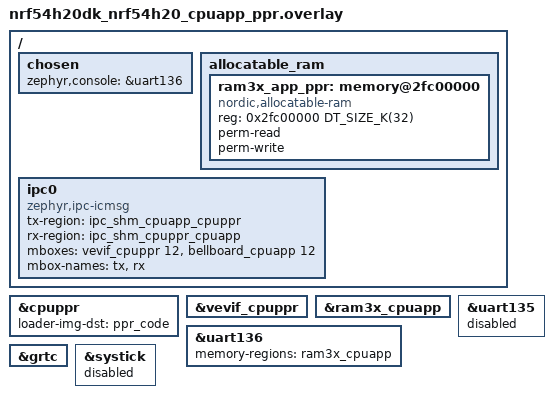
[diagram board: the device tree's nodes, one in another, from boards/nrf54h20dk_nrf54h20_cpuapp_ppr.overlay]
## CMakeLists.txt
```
#
# Copyright (c) 2022 Nordic Semiconductor ASA
#
# SPDX-License-Identifier: Apache-2.0
#

cmake_minimum_required(VERSION 3.20.0)

if (CONF_FILE AND NOT DEFINED DTC_OVERLAY_FILE)
  if(${CONF_FILE} MATCHES "prj_(.*).conf")
    set(DTC_OVERLAY_FILE "${CMAKE_MATCH_1}.overlay")
  endif()
endif()

# Use config file with the same name in remote.
if (CONF_FILE AND NOT DEFINED remote_CONF_FILE)
  set(remote_CONF_FILE ${CONF_FILE})
endif()

# Use DTC overlay file with the same name in remote
if (DTC_OVERLAY_FILE AND NOT DEFINED remote_DTC_OVERLAY_FILE)
  set(remote_DTC_OVERLAY_FILE ${DTC_OVERLAY_FILE})
endif()

# Use config overlay with the same name in remote.
if(OVERLAY_CONFIG AND NOT DEFINED remote_OVERLAY_CONFIG)
  set(remote_OVERLAY_CONFIG ${OVERLAY_CONFIG})
endif()

set(ZEPHYR_EXTRA_MODULES ${CMAKE_CURRENT_LIST_DIR})

find_package(Zephyr REQUIRED HINTS $ENV{ZEPHYR_BASE})
project(ipc_service_host)

target_sources(app PRIVATE src/main.c)
```

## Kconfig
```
#
# Copyright (c) 2022 Nordic Semiconductor ASA
#
# SPDX-License-Identifier: LicenseRef-Nordic-5-Clause
#

source "Kconfig.zephyr"
rsource "Kconfig.app"

config APP_INCLUDE_REMOTE_IMAGE
	bool "Include remote image as sub image"
	depends on SOC_NRF5340_CPUAPP || SOC_PLATFORM_HALTIUM
	default y if (BOARD_NRF5340DK_NRF5340_CPUAPP || BOARD_NRF5340DK_NRF5340_CPUAPPNS)
	default y if (BOARD_NRF54H20DK_NRF54H20_CPUAPP || BOARD_NRF7140DK_NRF7140_CPUAPP || BOARD_NRF9230DK_NRF9230_CPUAPP)
	select PARTITION_MANAGER_ENABLED if SOC_NRF5340_CPUAPP
	select BOARD_ENABLE_CPUNET if (BOARD_NRF5340DK_NRF5340_CPUAPP || BOARD_NRF5340DK_NRF5340_CPUAPPNS)

config APP_REMOTE_BOARD
	string "The name of the board to be used by remote image"
	depends on APP_INCLUDE_REMOTE_IMAGE
	default DOMAIN_CPUNET_BOARD if (BOARD_NRF5340DK_NRF5340_CPUAPP || BOARD_NRF5340DK_NRF5340_CPUAPPNS)
	default "nrf54h20dk_nrf54h20_cpuppr@soc1" if (BOARD_NRF54H20DK_NRF54H20_CPUAPP && HW_REVISION_SOC1)
	default "nrf7140dk_nrf7140_cpuppr" if BOARD_NRF7140DK_NRF7140_CPUAPP
	default "nrf9230dk_nrf9230_cpuppr" if BOARD_NRF9230DK_NRF9230_CPUAPP
```

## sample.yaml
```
sample:
    name: IPC Service integration test
    description: IPC Service integration and efficiency test
tests:
  sample.ipc.ipc_service.rpmsg_default:
    build_only: true
    platform_allow: nrf5340dk_nrf5340_cpuapp
    integration_platforms:
      - nrf5340dk_nrf5340_cpuapp
    tags: ipc
  sample.ipc.ipc_service.rpmsg_cpuapp_sending:
    build_only: true
    platform_allow: nrf5340dk_nrf5340_cpuapp
    integration_platforms:
      - nrf5340dk_nrf5340_cpuapp
    tags: ipc
    extra_args:
      OVERLAY_CONFIG=overlay-cpuapp-sending.conf
  sample.ipc.ipc_service.rpmsg_cpunet_sending:
    build_only: true
    platform_allow: nrf5340dk_nrf5340_cpuapp
    integration_platforms:
      - nrf5340dk_nrf5340_cpuapp
    tags: ipc
    extra_args:
      OVERLAY_CONFIG=overlay-cpunet-sending.conf
  sample.ipc.ipc_service.icmsg_default:
    build_only: true
    platform_allow: nrf5340dk_nrf5340_cpuapp
    integration_platforms:
      - nrf5340dk_nrf5340_cpuapp
    tags: ipc
    extra_args:
      CONF_FILE=prj_icmsg.conf
  sample.ipc.ipc_service.icmsg_cpuapp_sending:
    build_only: true
    platform_allow: nrf5340dk_nrf5340_cpuapp
    integration_platforms:
      - nrf5340dk_nrf5340_cpuapp
    tags: ipc
    extra_args:
      CONF_FILE=prj_icmsg.conf
      OVERLAY_CONFIG=overlay-cpuapp-sending.conf
  sample.ipc.ipc_service.icmsg_cpunet_sending:
    build_only: true
    platform_allow: nrf5340dk_nrf5340_cpuapp
    integration_platforms:
      - nrf5340dk_nrf5340_cpuapp
    tags: ipc
    extra_args:
      CONF_FILE=prj_icmsg.conf
      OVERLAY_CONFIG=overlay-cpunet-sending.conf

# Haltium Platform
  sample.ipc.ipc_service.nrf54_app_rad_icmsg:
    build_only: true
    platform_allow: nrf54h20dk_nrf54h20_cpuapp@soc1
    integration_platforms:
      - nrf54h20dk_nrf54h20_cpuapp@soc1
    tags: ipc
    extra_args:
      CONF_FILE=prj_icmsg.conf
      OVERLAY_CONFIG=boards/nrf54h20dk_nrf54h20_cpuapp_rad.conf
      DTC_OVERLAY_FILE=boards/nrf54h20dk_nrf54h20_cpuapp_rad_icmsg.overlay

  sample.ipc.ipc_service.nrf54_app_rad_rpmsg:
    build_only: true
    platform_allow: nrf54h20dk_nrf54h20_cpuapp@soc1
    integration_platforms:
      - nrf54h20dk_nrf54h20_cpuapp@soc1
    tags: ipc
    extra_args:
      OVERLAY_CONFIG=boards/nrf54h20dk_nrf54h20_cpuapp_rad.conf
      DTC_OVERLAY_FILE=boards/nrf54h20dk_nrf54h20_cpuapp_rad.overlay
      CONFIG_APP_IPC_SERVICE_SEND_INTERVAL=100
      remote_CONFIG_APP_IPC_SERVICE_SEND_INTERVAL=100

  sample.ipc.ipc_service.nrf54_app_rad_gpio_latency_icmsg:
    build_only: true
    platform_allow: nrf54h20dk_nrf54h20_cpuapp@soc1
    integration_platforms:
      - nrf54h20dk_nrf54h20_cpuapp@soc1
    tags: ipc
    extra_args:
      CONF_FILE=prj_icmsg.conf
      OVERLAY_CONFIG=boards/nrf54h20dk_nrf54h20_cpuapp_rad.conf
      DTC_OVERLAY_FILE=boards/nrf54h20dk_nrf54h20_cpuapp_rad_icmsg.overlay;boards/nrf54h20dk_nrf54h20_cpuapp_gpio_latency.overlay
      remote_DTC_OVERLAY_FILE=boards/nrf54h20dk_nrf54h20_cpuapp_rad_icmsg.overlay;boards/nrf54h20dk_nrf54h20_cpurad_gpio_latency.overlay
      CONFIG_APP_IPC_SERVICE_SEND_INTERVAL=10000
      remote_CONFIG_APP_IPC_SERVICE_SEND_INTERVAL=10000
      CONFIG_GPIO=y
      remote_CONFIG_GPIO=y
  sample.ipc.ipc_service.nrf54_app_rad_gpio_latency_rpmsg:
    build_only: true
    platform_allow: nrf54h20dk_nrf54h20_cpuapp@soc1
    integration_platforms:
      - nrf54h20dk_nrf54h20_cpuapp@soc1
    tags: ipc
    extra_args:
      OVERLAY_CONFIG=boards/nrf54h20dk_nrf54h20_cpuapp_rad.conf
      DTC_OVERLAY_FILE=boards/nrf54h20dk_nrf54h20_cpuapp_rad.overlay;boards/nrf54h20dk_nrf54h20_cpuapp_gpio_latency.overlay
      remote_DTC_OVERLAY_FILE=boards/nrf54h20dk_nrf54h20_cpuapp_rad.overlay;boards/nrf54h20dk_nrf54h20_cpurad_gpio_latency.overlay
      CONFIG_APP_IPC_SERVICE_SEND_INTERVAL=10000
      remote_CONFIG_APP_IPC_SERVICE_SEND_INTERVAL=10000
      CONFIG_GPIO=y
      remote_CONFIG_GPIO=y

  sample.ipc.ipc_service.nrf54_app_ppr_icmsg:
    build_only: true
    platform_allow: nrf54h20dk_nrf54h20_cpuapp@soc1
    integration_platforms:
      - nrf54h20dk_nrf54h20_cpuapp@soc1
    tags: ipc
    extra_args:
      CONF_FILE=prj_icmsg.conf
      OVERLAY_CONFIG=boards/nrf54h20dk_nrf54h20_cpuapp_ppr.conf
      DTC_OVERLAY_FILE=boards/nrf54h20dk_nrf54h20_cpuapp_ppr.overlay

  sample.ipc.ipc_service.nrf54_app_sys_icmsg:
    build_only: true
    platform_allow: nrf54h20dk_nrf54h20_cpuapp@soc1
    integration_platforms:
      - nrf54h20dk_nrf54h20_cpuapp@soc1
    tags: ipc
    extra_args:
      CONF_FILE=prj_icmsg.conf
      OVERLAY_CONFIG=boards/nrf54h20dk_nrf54h20_cpuapp_sys.conf
      DTC_OVERLAY_FILE=boards/nrf54h20dk_nrf54h20_cpuapp_sys_icmsg.overlay

  sample.ipc.ipc_service.nrf54_rad_sys_icmsg:
    build_only: true
    platform_allow: nrf54h20dk_nrf54h20_cpurad@soc1
    integration_platforms:
      - nrf54h20dk_nrf54h20_cpurad@soc1
    tags: ipc
    extra_args:
      CONF_FILE=prj_icmsg.conf
      OVERLAY_CONFIG=boards/nrf54h20dk_nrf54h20_cpurad_sys.conf
      DTC_OVERLAY_FILE=boards/nrf54h20dk_nrf54h20_cpurad_sys_icmsg.overlay

  sample.ipc.ipc_service.nrf71_app_ppr_icmsg:
    build_only: true
    platform_allow: nrf7140dk_nrf7140_cpuapp
    integration_platforms:
      - nrf7140dk_nrf7140_cpuapp
    tags: ipc
    extra_args:
      CONF_FILE=prj_icmsg.conf
      OVERLAY_CONFIG=boards/nrf7140dk_nrf7140_cpuapp_ppr.conf
      DTC_OVERLAY_FILE=boards/nrf7140dk_nrf7140_cpuapp_ppr.overlay

  sample.ipc.ipc_service.nrf92_app_ppr_icmsg:
    build_only: true
    platform_allow: nrf9230dk_nrf9230_cpuapp
    integration_platforms:
      - nrf9230dk_nrf9230_cpuapp
    tags: ipc
    extra_args:
      CONF_FILE=prj_icmsg.conf
      OVERLAY_CONFIG=boards/nrf9230dk_nrf9230_cpuapp_ppr.conf
      DTC_OVERLAY_FILE=boards/nrf9230dk_nrf9230_cpuapp_ppr.overlay
      remote_CONFIG_EMULATOR_FPGA=y
      CONFIG_EMULATOR_FPGA=y

  sample.ipc.ipc_service.nrf92_app_rad_icmsg:
    build_only: true
    platform_allow: nrf9230dk_nrf9230_cpuapp
    integration_platforms:
      - nrf9230dk_nrf9230_cpuapp
    tags: ipc
    extra_args:
      CONF_FILE=prj_icmsg.conf
      OVERLAY_CONFIG=boards/nrf9230dk_nrf9230_cpuapp_rad.conf
      DTC_OVERLAY_FILE=boards/nrf9230dk_nrf9230_cpuapp_rad_icmsg.overlay
      remote_CONFIG_EMULATOR_FPGA=y
      CONFIG_EMULATOR_FPGA=y

  sample.ipc.ipc_service.nrf92_app_sys_icmsg:
    build_only: true
    platform_allow: nrf9230dk_nrf9230_cpuapp
    integration_platforms:
      - nrf9230dk_nrf9230_cpuapp
    tags: ipc
    extra_args:
      CONF_FILE=prj_icmsg.conf
      OVERLAY_CONFIG=boards/nrf9230dk_nrf9230_cpuapp_sys.conf
      DTC_OVERLAY_FILE=boards/nrf9230dk_nrf9230_cpuapp_sys_icmsg.overlay
      remote_CONFIG_EMULATOR_FPGA=y
      CONFIG_EMULATOR_FPGA=y

  sample.ipc.ipc_service.nrf92_rad_sys_icmsg:
    build_only: true
    platform_allow: nrf9230dk_nrf9230_cpurad
    integration_platforms:
      - nrf9230dk_nrf9230_cpurad
    tags: ipc
    extra_args:
      CONF_FILE=prj_icmsg.conf
      OVERLAY_CONFIG=boards/nrf9230dk_nrf9230_cpurad_sys.conf
      DTC_OVERLAY_FILE=boards/nrf9230dk_nrf9230_cpurad_sys_icmsg.overlay
      remote_CONFIG_EMULATOR_FPGA=y
      CONFIG_EMULATOR_FPGA=y

  sample.ipc.ipc_service.nrf92_app_mod_icmsg:
    build_only: true
    platform_allow: nrf9230dk_nrf9230_cpuapp
    integration_platforms:
      - nrf9230dk_nrf9230_cpuapp
    tags: ipc
    extra_args:
      CONF_FILE=prj_icmsg.conf
      OVERLAY_CONFIG=boards/nrf9230dk_nrf9230_cpuapp_mod.conf
      DTC_OVERLAY_FILE=boards/nrf9230dk_nrf9230_cpuapp_mod_icmsg.overlay
      remote_CONFIG_EMULATOR_FPGA=y
      CONFIG_EMULATOR_FPGA=y

  sample.ipc.ipc_service.nrf92_app_rad_rpmsg:
    build_only: true
    platform_allow: nrf9230dk_nrf9230_cpuapp
    integration_platforms:
      - nrf9230dk_nrf9230_cpuapp
    tags: ipc
    extra_args:
      OVERLAY_CONFIG=boards/nrf9230dk_nrf9230_cpuapp_rad.conf
      DTC_OVERLAY_FILE=boards/nrf9230dk_nrf9230_cpuapp_rad.overlay
      CONFIG_APP_IPC_SERVICE_SEND_INTERVAL=100
      remote_CONFIG_APP_IPC_SERVICE_SEND_INTERVAL=100
      remote_CONFIG_EMULATOR_FPGA=y
      CONFIG_EMULATOR_FPGA=y

  sample.ipc.ipc_service.nrf92_app_mod_rpmsg:
    build_only: true
    platform_allow: nrf9230dk_nrf9230_cpuapp
    integration_platforms:
      - nrf9230dk_nrf9230_cpuapp
    tags: ipc
    extra_args:
      OVERLAY_CONFIG=boards/nrf9230dk_nrf9230_cpuapp_mod.conf
      DTC_OVERLAY_FILE=boards/nrf9230dk_nrf9230_cpuapp_mod.overlay
      CONFIG_APP_IPC_SERVICE_SEND_INTERVAL=100
      remote_CONFIG_APP_IPC_SERVICE_SEND_INTERVAL=100
      remote_CONFIG_EMULATOR_FPGA=y
      CONFIG_EMULATOR_FPGA=y
```

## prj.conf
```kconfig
CONFIG_IPC_SERVICE=y

CONFIG_PRINTK=y
CONFIG_LOG=y
CONFIG_IPC_SERVICE_LOG_LEVEL_INF=y
CONFIG_IPC_SERVICE_BACKEND_RPMSG=y
CONFIG_IPC_SERVICE_STATIC_VRINGS_MEM_ALIGNMENT=32
CONFIG_MBOX=y

# required to allocate virtqueues
CONFIG_HEAP_MEM_POOL_SIZE=4096

CONFIG_OPENAMP=y
CONFIG_OPENAMP_SLAVE=n
CONFIG_OPENAMP_WITH_DCACHE=y

CONFIG_LOG_PROCESS_THREAD_PRIORITY=-15
CONFIG_LOG_PROCESS_THREAD_CUSTOM_PRIORITY=y
```

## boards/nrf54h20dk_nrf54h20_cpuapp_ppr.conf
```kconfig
#
# Copyright (c) 2022 Nordic Semiconductor ASA
#
# SPDX-License-Identifier: LicenseRef-Nordic-5-Clause
#

CONFIG_MBOX_NRFX_IDS=y

CONFIG_APP_IPC_SERVICE_SEND_INTERVAL=900

CONFIG_UART_CONSOLE=y
CONFIG_CONSOLE=y
CONFIG_SERIAL=y
```

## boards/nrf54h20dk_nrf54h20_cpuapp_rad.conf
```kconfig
#
# Copyright (c) 2022 Nordic Semiconductor ASA
#
# SPDX-License-Identifier: LicenseRef-Nordic-5-Clause
#

CONFIG_MBOX_NRFX_IDS=y
CONFIG_APP_REMOTE_BOARD="nrf54h20dk_nrf54h20_cpurad@soc1"

CONFIG_APP_IPC_SERVICE_SEND_INTERVAL=900

CONFIG_UART_CONSOLE=y
CONFIG_CONSOLE=y
CONFIG_SERIAL=y
```

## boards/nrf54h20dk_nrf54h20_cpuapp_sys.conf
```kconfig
#
# Copyright (c) 2022 Nordic Semiconductor ASA
#
# SPDX-License-Identifier: LicenseRef-Nordic-5-Clause
#

CONFIG_MBOX_NRFX_IDS=y
CONFIG_APP_REMOTE_BOARD="nrf54h20dk_nrf54h20_cpusys@soc1"
CONFIG_INCLUDE_SYSCTRL=n

CONFIG_APP_IPC_SERVICE_SEND_INTERVAL=900

CONFIG_UART_CONSOLE=y
CONFIG_CONSOLE=y
CONFIG_SERIAL=y
```

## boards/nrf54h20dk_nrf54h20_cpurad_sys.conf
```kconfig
#
# Copyright (c) 2022 Nordic Semiconductor ASA
#
# SPDX-License-Identifier: LicenseRef-Nordic-5-Clause
#

CONFIG_MBOX_NRFX_IDS=y
CONFIG_APP_INCLUDE_REMOTE_IMAGE=y
CONFIG_APP_REMOTE_BOARD="nrf54h20dk_nrf54h20_cpusys@soc1"
CONFIG_INCLUDE_SYSCTRL=n

CONFIG_APP_IPC_SERVICE_SEND_INTERVAL=900

CONFIG_UART_CONSOLE=y
CONFIG_CONSOLE=y
CONFIG_SERIAL=y
```

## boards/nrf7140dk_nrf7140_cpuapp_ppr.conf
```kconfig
#
# Copyright (c) 2023 Nordic Semiconductor ASA
#
# SPDX-License-Identifier: LicenseRef-Nordic-5-Clause
#

CONFIG_MBOX_NRFX_IDS=y

CONFIG_APP_IPC_SERVICE_SEND_INTERVAL=900

CONFIG_UART_CONSOLE=y
CONFIG_CONSOLE=y
CONFIG_SERIAL=y
```

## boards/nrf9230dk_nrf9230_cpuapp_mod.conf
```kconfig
#
# Copyright (c) 2023 Nordic Semiconductor ASA
#
# SPDX-License-Identifier: LicenseRef-Nordic-5-Clause
#

CONFIG_MBOX_NRFX_IDS=y
CONFIG_APP_REMOTE_BOARD="nrf9230dk_nrf9230_cpumod"

CONFIG_APP_IPC_SERVICE_SEND_INTERVAL=900

CONFIG_UART_CONSOLE=y
CONFIG_CONSOLE=y
CONFIG_SERIAL=y
```

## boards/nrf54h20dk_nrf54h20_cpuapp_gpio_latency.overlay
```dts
/*
 * Copyright (c) 2023 Nordic Semiconductor ASA
 *
 * SPDX-License-Identifier: Apache-2.0
 *
 * This file is used to add the pins that would go high
 * when the ipc_service_send function is called and
 * while the receiving callback is processing the data.
 */

/ {
	ipc_send_pin: ipc-send-pin {
		compatible = "nordic,gpio-pins";
		gpios = <&gpio0 0 GPIO_ACTIVE_HIGH>;
		status = "okay";
	};

	ipc_recv_pin: ipc-recv-pin {
		compatible = "nordic,gpio-pins";
		gpios = <&gpio0 1 GPIO_ACTIVE_HIGH>;
		status = "okay";
	};
};

&gpio0 {
	status = "okay";
};
```

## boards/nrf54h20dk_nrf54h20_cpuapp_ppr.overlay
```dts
/*
 * Copyright (c) 2022 Nordic Semiconductor ASA
 *
 * SPDX-License-Identifier: LicenseRef-Nordic-5-Clause
 */



/ {
	chosen {
		zephyr,console = &uart136;
	};

	allocatable_ram {
		#address-cells = <1>;
		#size-cells = <1>;

		/* Configure RAM region.
		 * This is done to ensure correct UICR generation.
		 */
		ram3x_app_ppr: memory@2fc00000 {
			compatible = "nordic,allocatable-ram";
			reg = <0x2fc00000 DT_SIZE_K(32)>;
			perm-read;
			perm-write;
		};
	};

	ipc0: ipc0 {
		compatible = "zephyr,ipc-icmsg";
		tx-region = <&ipc_shm_cpuapp_cpuppr>;
		rx-region = <&ipc_shm_cpuppr_cpuapp>;
		mboxes = <&vevif_cpuppr 12>,
			 <&bellboard_cpuapp  12>;
		mbox-names = "tx", "rx";
		status = "okay";
	};
};

&cpuppr {
	loader-img-dst = <&ppr_code>;
	status = "okay";
};

&vevif_cpuppr {
       status = "okay";
};

&ram3x_cpuapp {
	status = "okay";
};

&uart136 {
	status = "okay";
	memory-regions = <&ram3x_cpuapp>;
};

&uart135 {
	status = "reserved";
};

&grtc {
	status = "okay";
};

&systick {
	status = "disabled";
};
```

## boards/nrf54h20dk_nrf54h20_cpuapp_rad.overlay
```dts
/*
 * Copyright (c) 2022 Nordic Semiconductor ASA
 *
 * SPDX-License-Identifier: Apache-2.0
 */

#include <common/nordic_nrf_next/nrfx_ram3x_dma.dtsi>

/{
	chosen {
		zephyr,console = &uart136;
		zephyr,sram = &cpuapp_ram0;
	};

	ipc0: ipc0 {
		compatible = "zephyr,ipc-openamp-static-vrings";
		memory-region = <&ipc_shm_area_cpuapp_cpurad>;
		mboxes = <&bellboard_cpurad 12>,
			 <&bellboard_cpuapp 18>;
		mbox-names = "tx", "rx";
		role = "host";
		status = "okay";
	};
};

/* ram3x_cpuapp buffer is used by App core UART driver. */
&ram3x_cpuapp {
	status = "okay";
};

&uart136 {
	status = "okay";
	memory-regions = <&ram3x_cpuapp>;
};
```

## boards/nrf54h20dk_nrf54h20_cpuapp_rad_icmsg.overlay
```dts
/*
 * Copyright (c) 2022 Nordic Semiconductor ASA
 *
 * SPDX-License-Identifier: Apache-2.0
 */


/{
	chosen {
		zephyr,console = &uart136;
	};

	allocatable_ram {
		#address-cells = <1>;
		#size-cells = <1>;

		ram3x_app_mem: memory@2fc00000 {
			compatible = "nordic,allocatable-ram";
			reg = <0x2fc00000 DT_SIZE_K(32)>;
			perm-read;
			perm-write;
		};
	};
};

&ipc_cpurad {
	compatible = "zephyr,ipc-icmsg";
	tx-region = <&ipc_shm_cpuapp_cpurad>;
	rx-region = <&ipc_shm_cpurad_cpuapp>;
	status = "okay";
	/delete-property/ memory-region;
	/delete-property/ role;
};

ipc0: &ipc_cpurad { };

/* ram3x_cpuapp buffer is used by App core UART driver. */
&ram3x_cpuapp {
	status = "okay";
};

&uart136 {
	status = "okay";
	memory-regions = <&ram3x_cpuapp>;
};
```

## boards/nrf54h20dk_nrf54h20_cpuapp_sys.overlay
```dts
/*
 * Copyright (c) 2022 Nordic Semiconductor ASA
 *
 * SPDX-License-Identifier: Apache-2.0
 */

#include <common/nordic_nrf_next/nrfx_ram3x_dma.dtsi>
#include "shared/nrf54_ipc_shm_ram2.dtsi"

/{
	chosen {
		zephyr,console = &uart136;
	};

	ipc0: ipc0 {
		compatible = "zephyr,ipc-openamp-static-vrings";
		memory-region = <&ipc_shm_ram>;
		mboxes = <&vevif_cpusys 12>,
			 <&bellboard_cpuapp 6>;
		mbox-names = "tx", "rx";
		role = "host";
		status = "okay";
	};
};

&vevif_cpusys {
	status = "okay";
};

/* ram3x_cpuapp buffer is used by App core UART driver. */
&ram3x_cpuapp {
	status = "okay";
};

&uart135 {
	status = "disabled";
};

&uart136 {
	status = "okay";
	memory-regions = <&ram3x_cpuapp>;
};
```

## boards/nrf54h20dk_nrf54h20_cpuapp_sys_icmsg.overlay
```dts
/*
 * Copyright (c) 2022 Nordic Semiconductor ASA
 *
 * SPDX-License-Identifier: Apache-2.0
 */

#include <common/nordic_nrf_next/nrfx_ram3x_dma.dtsi>
#include "shared/nrf54_ipc_shm_ram2.dtsi"

/ {
	chosen {
		zephyr,console = &uart136;
	};

	ipc0: ipc0 {
		compatible = "zephyr,ipc-icmsg";
		tx-region = <&ipc_shm_remote>;
		rx-region = <&ipc_shm_local>;
		mboxes = <&vevif_cpusys 12>,
			 <&bellboard_cpuapp 6>;
		mbox-names = "tx", "rx";
		status = "okay";
	};
};

&vevif_cpusys {
	status = "okay";
};

/* ram3x_cpuapp buffer is used by App core UART driver. */
&ram3x_cpuapp {
	status = "okay";
};

&uart135 {
	status = "disabled";
};

&uart136 {
	status = "okay";
	memory-regions = <&ram3x_cpuapp>;
};
```

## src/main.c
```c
/*
 * Copyright (c) 2022 Nordic Semiconductor ASA
 *
 * SPDX-License-Identifier: Apache-2.0
 */

#include <zephyr/kernel.h>
#include <zephyr/device.h>
#include <zephyr/drivers/gpio.h>
#include <string.h>

#include <zephyr/logging/log.h>

#include <zephyr/ipc/ipc_service.h>

#ifdef CONFIG_TEST_EXTRA_STACK_SIZE
#define STACKSIZE	(1024 + CONFIG_TEST_EXTRA_STACK_SIZE)
#else
#define STACKSIZE	(1024)
#endif

static const struct gpio_dt_spec pin_send =
	GPIO_DT_SPEC_GET_OR(DT_NODELABEL(ipc_send_pin), gpios, {0});
static const struct gpio_dt_spec pin_recv =
	GPIO_DT_SPEC_GET_OR(DT_NODELABEL(ipc_recv_pin), gpios, {0});

LOG_MODULE_REGISTER(host, LOG_LEVEL_INF);

struct payload {
	unsigned long cnt;
	unsigned long size;
	uint8_t data[];
};

static K_SEM_DEFINE(bound_sem, 0, 1);
K_THREAD_STACK_DEFINE(check_task_stack, STACKSIZE);
struct k_thread check_task_data;

static uint32_t payload_data[(CONFIG_APP_IPC_SERVICE_MESSAGE_LEN + 3)/4];
static struct payload *p_payload = (struct payload *) payload_data;

static void ep_bound(void *priv)
{
	k_sem_give(&bound_sem);
}

static void ep_recv(const void *data, size_t len, void *priv)
{
	uint8_t received_val = *((uint8_t *)data);
	static uint8_t expected_val;

	if (pin_recv.port) {
		gpio_pin_set_dt(&pin_recv, 1);
	}

	if ((received_val != expected_val) || (len != CONFIG_APP_IPC_SERVICE_MESSAGE_LEN)) {
		printk("Unexpected message received_val: %d , expected_val: %d\n",
			received_val,
			expected_val);
	}

	expected_val++;
	if (pin_recv.port) {
		gpio_pin_set_dt(&pin_recv, 0);
	}
}

static struct ipc_ept_cfg ep_cfg = {
	.name = "ep0",
	.cb = {
		.bound    = ep_bound,
		.received = ep_recv,
	},
};

static void check_task(void *arg1, void *arg2, void *arg3)
{
	ARG_UNUSED(arg1);
	ARG_UNUSED(arg2);
	ARG_UNUSED(arg3);

	unsigned long last_cnt = p_payload->cnt;
	unsigned long delta;

	while (1) {
		k_sleep(K_MSEC(1000));

		delta = p_payload->cnt - last_cnt;

		printk("Δpkt: %ld (%ld B/pkt) | throughput: %ld bit/s\n",
			delta, p_payload->size, delta * CONFIG_APP_IPC_SERVICE_MESSAGE_LEN * 8);

		last_cnt = p_payload->cnt;
	}
}

int main(void)
{
	const struct device *ipc0_instance;
	struct ipc_ept ep;
	int ret;
	printk("IPC-service %s demo started\n", CONFIG_BOARD);

	if (pin_send.port) {
		gpio_pin_configure_dt(&pin_send, GPIO_OUTPUT_INACTIVE);
	}
	if (pin_recv.port) {
		gpio_pin_configure_dt(&pin_recv, GPIO_OUTPUT_INACTIVE);
	}

	memset(p_payload->data, 0xA5, CONFIG_APP_IPC_SERVICE_MESSAGE_LEN - sizeof(struct payload));

	p_payload->size = CONFIG_APP_IPC_SERVICE_MESSAGE_LEN;
	p_payload->cnt = 0;

	ipc0_instance = DEVICE_DT_GET(DT_NODELABEL(ipc0));

	ret = ipc_service_open_instance(ipc0_instance);
	if ((ret < 0) && (ret != -EALREADY)) {
		LOG_INF("ipc_service_open_instance() failure: %d", ret);
		return ret;
	}

	ret = ipc_service_register_endpoint(ipc0_instance, &ep, &ep_cfg);
	if (ret < 0) {
		printf("ipc_service_register_endpoint() failure");
		return ret;
	}

	k_sem_take(&bound_sem, K_FOREVER);

	(void)k_thread_create(
		&check_task_data, check_task_stack,
		K_THREAD_STACK_SIZEOF(check_task_stack),
		check_task,
		NULL, NULL, NULL,
		-1, 0, K_NO_WAIT);

	while (true) {
		if (pin_send.port) {
			gpio_pin_set_dt(&pin_send, 1);
		}
		ret = ipc_service_send(&ep, p_payload, CONFIG_APP_IPC_SERVICE_MESSAGE_LEN);
		if (pin_send.port) {
			gpio_pin_set_dt(&pin_send, 0);
		}
		if (ret == -ENOMEM) {
			/* No space in the buffer. Retry. */
			LOG_DBG("send_message(%ld) failed with ret -ENOMEM\n", p_payload->cnt);
		} else if (ret < 0) {
			LOG_ERR("send_message(%ld) failed with ret %d\n", p_payload->cnt, ret);
			break;
		} else {
			p_payload->cnt++;
		}

		if (CONFIG_APP_IPC_SERVICE_SEND_INTERVAL < (USEC_PER_SEC / CONFIG_SYS_CLOCK_TICKS_PER_SEC)) {
			k_busy_wait(CONFIG_APP_IPC_SERVICE_SEND_INTERVAL);
		} else {
			k_usleep(CONFIG_APP_IPC_SERVICE_SEND_INTERVAL);
		}
	}

	return 0;
}
```
